VERSION ""

NS_ :

BS_:

BU_: TCU CANedge BMS TempSense INV U2C VCU

BO_ 3221225472 VECTOR__INDEPENDENT_SIG_MSG: 0 Vector__XXX
 SG_ ShockTravel_RL : 0|8@1+ (1,0) [0|255] "" Vector__XXX
 SG_ ShockTravel_RR : 0|8@1+ (1,0) [0|255] "" Vector__XXX
 SG_ ShockTravel_FL : 0|8@1+ (1,0) [0|255] "" Vector__XXX
 SG_ ShockTravel_FR : 0|8@1+ (1,0) [0|255] "" Vector__XXX

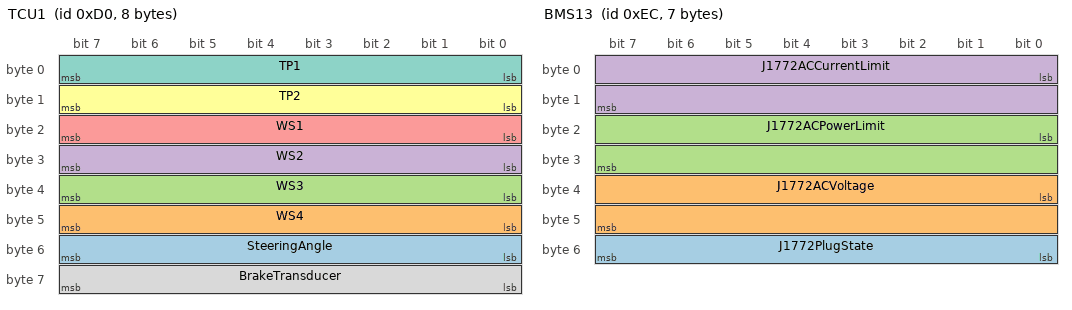
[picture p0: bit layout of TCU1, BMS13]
BO_ 208 TCU1: 8 TCU
 SG_ SteeringAngle : 48|8@1- (1,0) [-128|127] ""  CANedge
 SG_ WS4 : 40|8@1+ (1,0) [0|255] ""  CANedge
 SG_ WS3 : 32|8@1+ (1,0) [0|255] ""  CANedge
 SG_ WS2 : 24|8@1+ (1,0) [0|255] ""  CANedge
 SG_ WS1 : 16|8@1+ (1,0) [0|255] ""  CANedge
 SG_ TP2 : 8|8@1+ (1,0) [0|100] "%"  CANedge
 SG_ TP1 : 0|8@1+ (1,0) [0|100] "%"  CANedge
 SG_ BrakeTransducer : 56|8@1+ (1,0) [0|0] ""  CANedge

BO_ 237 BMS14: 4 BMS
 SG_ DTCStatus2 : 16|16@1+ (1,0) [0|65535] ""  CANedge
 SG_ DTCStatus1 : 0|16@1+ (1,0) [0|65535] ""  CANedge

BO_ 236 BMS13: 7 BMS
 SG_ J1772PlugState : 48|8@1+ (1,0) [0|4] ""  CANedge
 SG_ J1772ACVoltage : 32|16@1+ (0.1,0) [0|0] "VAC"  CANedge
 SG_ J1772ACPowerLimit : 16|16@1+ (1,0) [0|0] "WattAC"  CANedge
 SG_ J1772ACCurrentLimit : 0|16@1+ (1,0) [0|0] "AmpAC"  CANedge

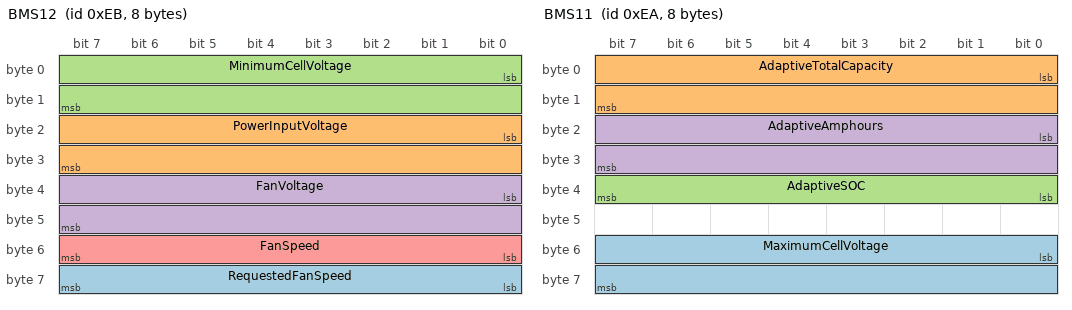
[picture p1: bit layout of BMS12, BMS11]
BO_ 235 BMS12: 8 BMS
 SG_ RequestedFanSpeed : 56|8@1+ (1,0) [0|6] ""  CANedge
 SG_ PowerInputVoltage : 16|16@1+ (0.1,0) [0|0] "V"  CANedge
 SG_ MinimumCellVoltage : 0|16@1+ (0.0001,0) [0|6.5535] "V"  CANedge
 SG_ FanVoltage : 32|16@1+ (0.01,0) [0|0] "V"  CANedge
 SG_ FanSpeed : 48|8@1+ (1,0) [0|6] ""  CANedge

BO_ 234 BMS11: 8 BMS
 SG_ MaximumCellVoltage : 48|16@1+ (0.0001,0) [0|6.5535] "V"  CANedge
 SG_ AdaptiveTotalCapacity : 0|16@1+ (0.1,0) [0|0] "Ah"  CANedge
 SG_ AdaptiveSOC : 32|8@1+ (0.5,0) [0|100] "%"  CANedge
 SG_ AdaptiveAmphours : 16|16@1+ (0.1,0) [0|0] "Ah"  CANedge

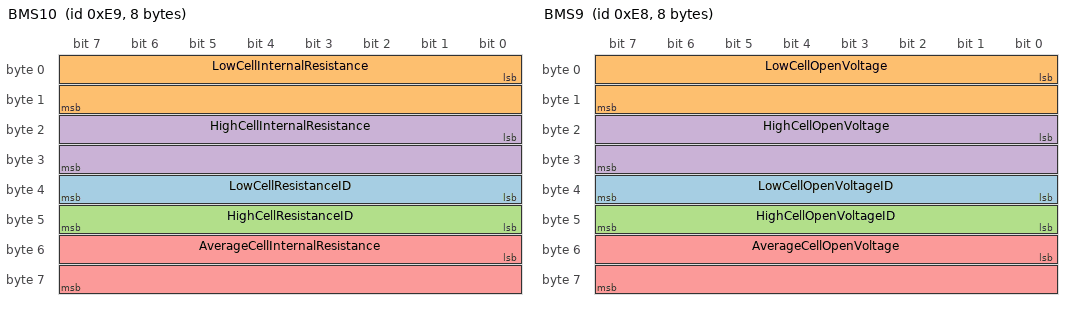
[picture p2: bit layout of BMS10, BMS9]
BO_ 233 BMS10: 8 BMS
 SG_ LowCellResistanceID : 32|8@1+ (1,0) [1|180] ""  CANedge
 SG_ LowCellInternalResistance : 0|16@1+ (0.01,0) [0|0] "mOhm"  CANedge
 SG_ HighCellResistanceID : 40|8@1+ (1,0) [1|180] ""  CANedge
 SG_ HighCellInternalResistance : 16|16@1+ (0.01,0) [0|0] "mOhm"  CANedge
 SG_ AverageCellInternalResistance : 48|16@1+ (0.01,0) [0|0] "mOhm"  CANedge

BO_ 232 BMS9: 8 BMS
 SG_ LowCellOpenVoltageID : 32|8@1+ (1,0) [1|180] ""  CANedge
 SG_ LowCellOpenVoltage : 0|16@1+ (0.0001,0) [0|6.5535] "V"  CANedge
 SG_ HighCellOpenVoltageID : 40|8@1+ (1,0) [1|180] ""  CANedge
 SG_ HighCellOpenVoltage : 16|16@1+ (0.0001,0) [0|6.5535] "V"  CANedge
 SG_ AverageCellOpenVoltage : 48|16@1+ (0.0001,0) [0|6.5535] "V"  CANedge

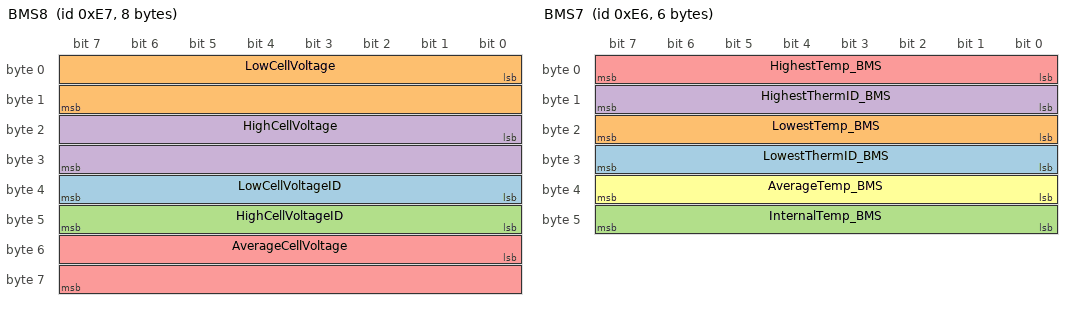
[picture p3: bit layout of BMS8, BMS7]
BO_ 231 BMS8: 8 BMS
 SG_ LowCellVoltageID : 32|8@1+ (1,0) [1|180] ""  CANedge
 SG_ LowCellVoltage : 0|16@1+ (0.0001,0) [0|6.5535] "V"  CANedge
 SG_ HighCellVoltageID : 40|8@1+ (1,0) [1|180] ""  CANedge
 SG_ HighCellVoltage : 16|16@1+ (0.0001,0) [0|6.5535] "V"  CANedge
 SG_ AverageCellVoltage : 48|16@1+ (0.0001,0) [0|6.5535] "V"  CANedge

BO_ 230 BMS7: 6 BMS
 SG_ LowestThermID_BMS : 24|8@1+ (1,0) [1|80] ""  CANedge
 SG_ LowestTemp_BMS : 16|8@1- (1,0) [0|255] "C"  CANedge
 SG_ InternalTemp_BMS : 40|8@1- (1,0) [0|255] "C"  CANedge
 SG_ HighestThermID_BMS : 8|8@1+ (1,0) [1|80] ""  CANedge
 SG_ HighestTemp_BMS : 0|8@1- (1,0) [0|255] "C"  CANedge
 SG_ AverageTemp_BMS : 32|8@1- (1,0) [0|255] "C"  CANedge

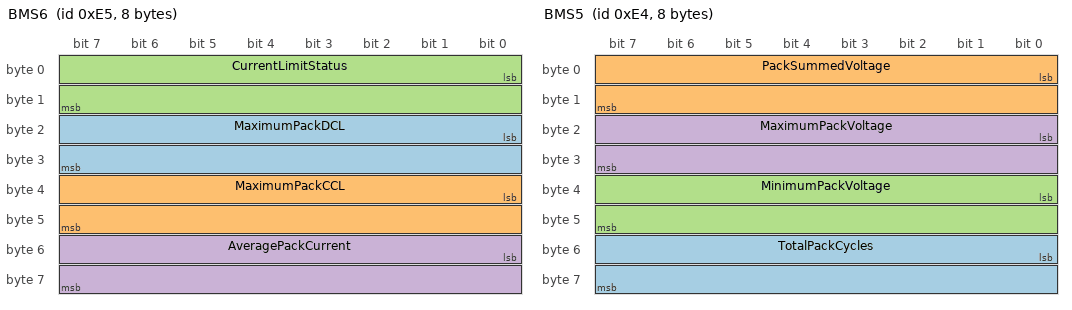
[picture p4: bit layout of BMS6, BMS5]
BO_ 229 BMS6: 8 BMS
 SG_ MaximumPackDCL : 16|16@1+ (1,0) [0|0] "A"  CANedge
 SG_ MaximumPackCCL : 32|16@1+ (1,0) [0|0] "A"  CANedge
 SG_ CurrentLimitStatus : 0|16@1+ (1,0) [0|65535] ""  CANedge
 SG_ AveragePackCurrent : 48|16@1+ (0.1,0) [0|0] "A"  CANedge

BO_ 228 BMS5: 8 BMS
 SG_ TotalPackCycles : 48|16@1+ (1,0) [0|0] "cycle"  CANedge
 SG_ PackSummedVoltage : 0|16@1+ (0.1,0) [0|0] "V"  CANedge
 SG_ MinimumPackVoltage : 32|16@1+ (0.1,0) [0|0] "V"  CANedge
 SG_ MaximumPackVoltage : 16|16@1+ (0.1,0) [0|0] "V"  CANedge

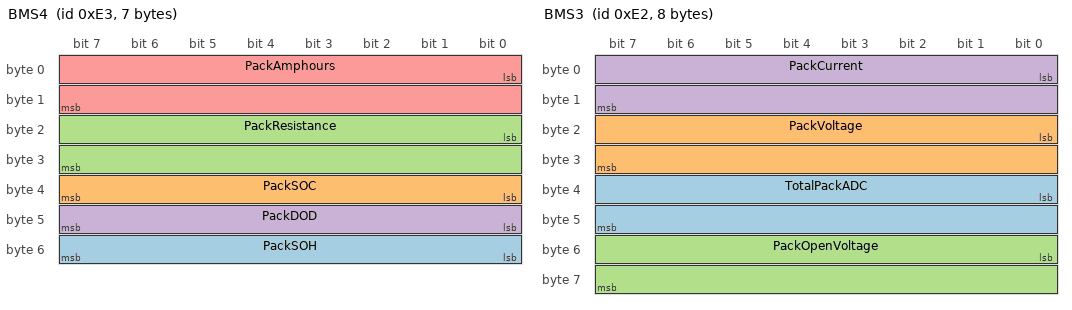
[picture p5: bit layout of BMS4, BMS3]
BO_ 227 BMS4: 7 BMS
 SG_ PackSOH : 48|8@1+ (1,0) [0|100] "%"  CANedge
 SG_ PackSOC : 32|8@1+ (0.5,0) [0|100] "%"  CANedge
 SG_ PackResistance : 16|16@1+ (1,0) [0|0] "mOhm"  CANedge
 SG_ PackDOD : 40|8@1+ (0.5,0) [0|100] "%"  CANedge
 SG_ PackAmphours : 0|16@1+ (0.1,0) [0|0] "Ahr"  CANedge

BO_ 226 BMS3: 8 BMS
 SG_ TotalPackADC : 32|16@1+ (0.1,0) [0|0] "V"  CANedge
 SG_ PackVoltage : 16|16@1+ (0.1,0) [0|0] "V"  CANedge
 SG_ PackOpenVoltage : 48|16@1+ (0.1,0) [0|0] "V"  CANedge
 SG_ PackCurrent : 0|16@1+ (0.1,0) [0|0] "A"  CANedge

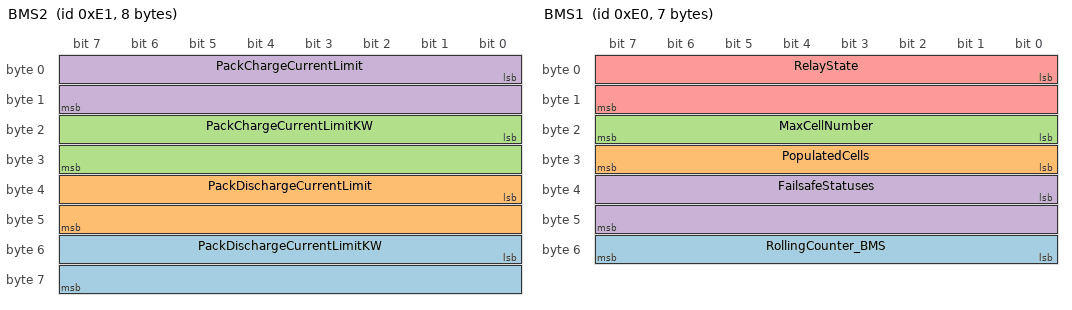
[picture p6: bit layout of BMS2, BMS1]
BO_ 225 BMS2: 8 BMS
 SG_ PackDischargeCurrentLimitKW : 48|16@1+ (0.1,0) [0|0] "kW"  CANedge
 SG_ PackDischargeCurrentLimit : 32|16@1+ (1,0) [0|0] "A"  CANedge
 SG_ PackChargeCurrentLimitKW : 16|16@1+ (0.1,0) [0|0] "kW"  CANedge
 SG_ PackChargeCurrentLimit : 0|16@1+ (1,0) [0|0] "A"  CANedge

BO_ 224 BMS1: 7 BMS
 SG_ RollingCounter_BMS : 48|8@1+ (1,0) [0|255] ""  CANedge
 SG_ PopulatedCells : 24|8@1+ (1,0) [0|255] ""  CANedge
 SG_ MaxCellNumber : 16|8@1+ (1,0) [0|255] ""  CANedge
 SG_ FailsafeStatuses : 32|16@1+ (1,0) [0|65535] ""  CANedge
 SG_ RelayState : 0|16@1+ (1,0) [0|65535] ""  CANedge

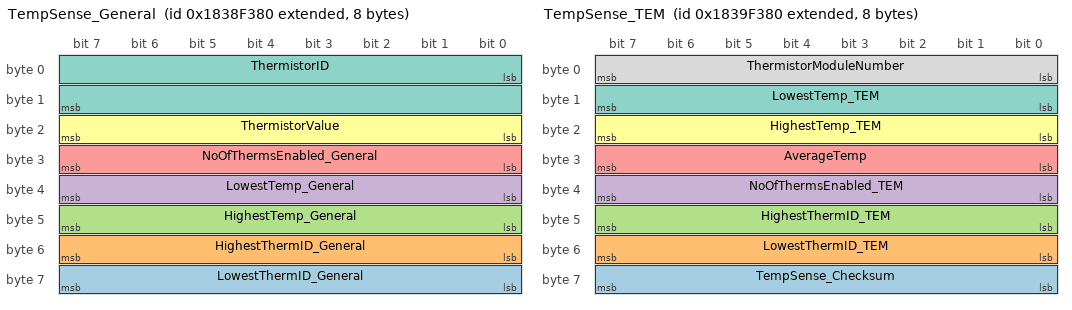
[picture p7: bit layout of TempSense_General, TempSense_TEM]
BO_ 2553869184 TempSense_General: 8 TempSense
 SG_ LowestThermID_General : 56|8@1+ (1,0) [0|79] ""  CANedge
 SG_ HighestThermID_General : 48|8@1+ (1,0) [0|79] ""  CANedge
 SG_ HighestTemp_General : 40|8@1- (1,0) [0|255] "C"  CANedge
 SG_ LowestTemp_General : 32|8@1- (1,0) [0|255] "C"  CANedge
 SG_ NoOfThermsEnabled_General : 24|8@1+ (1,0) [0|80] ""  CANedge
 SG_ ThermistorValue : 16|8@1- (1,0) [0|255] "C"  CANedge
 SG_ ThermistorID : 0|16@1+ (1,0) [0|799] ""  CANedge

BO_ 2553934720 TempSense_TEM: 8 TempSense
 SG_ TempSense_Checksum : 56|8@1+ (1,0) [0|255] ""  CANedge,BMS
 SG_ LowestThermID_TEM : 48|8@1+ (1,0) [0|79] ""  CANedge,BMS
 SG_ HighestThermID_TEM : 40|8@1+ (1,0) [0|79] ""  CANedge,BMS
 SG_ NoOfThermsEnabled_TEM : 32|8@1+ (1,0) [0|80] ""  CANedge,BMS
 SG_ AverageTemp : 24|8@1- (1,0) [0|255] "C"  CANedge,BMS
 SG_ HighestTemp_TEM : 16|8@1- (1,0) [0|255] "C"  CANedge,BMS
 SG_ LowestTemp_TEM : 8|8@1- (1,0) [0|255] "C"  CANedge,BMS
 SG_ ThermistorModuleNumber : 0|8@1+ (1,0) [0|9] ""  CANedge,BMS

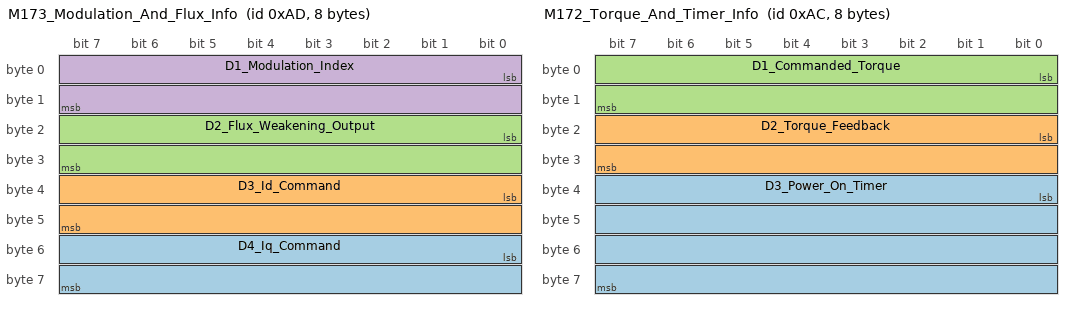
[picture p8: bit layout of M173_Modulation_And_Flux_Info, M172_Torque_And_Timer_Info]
BO_ 173 M173_Modulation_And_Flux_Info: 8 INV
 SG_ D4_Iq_Command : 48|16@1- (0.1,0) [-3276.8|3276.7] "A"  CANedge
 SG_ D3_Id_Command : 32|16@1- (0.1,0) [-3276.8|3276.7] "A"  CANedge
 SG_ D2_Flux_Weakening_Output : 16|16@1- (0.1,0) [-3276.8|3276.7] "A"  CANedge
 SG_ D1_Modulation_Index : 0|16@1- (0.0001,0) [-3.2768|3.2767] ""  CANedge

BO_ 172 M172_Torque_And_Timer_Info: 8 INV
 SG_ D3_Power_On_Timer : 32|32@1+ (0.003,0) [0|12884800] "Sec"  CANedge
 SG_ D2_Torque_Feedback : 16|16@1- (0.1,0) [-3276.8|3276.7] "Nm"  CANedge
 SG_ D1_Commanded_Torque : 0|16@1- (0.1,0) [-3276.8|3276.7] "Nm"  CANedge

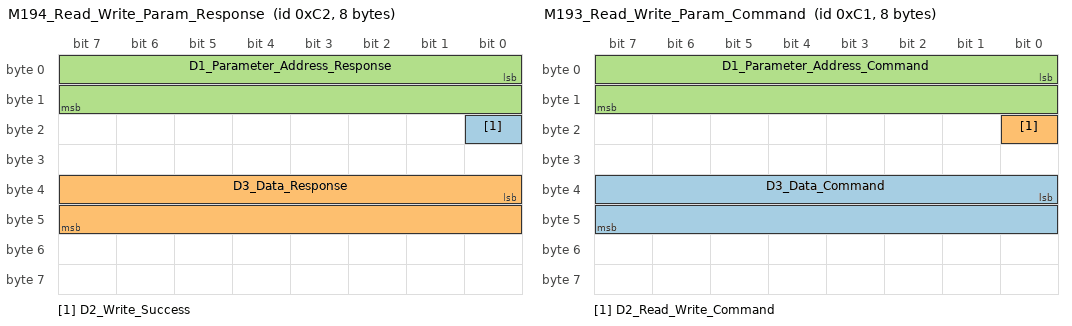
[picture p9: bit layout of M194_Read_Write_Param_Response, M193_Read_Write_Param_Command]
BO_ 194 M194_Read_Write_Param_Response: 8 INV
 SG_ D2_Write_Success : 16|1@1+ (1,0) [0|1] ""  CANedge
 SG_ D3_Data_Response : 32|16@1- (1,0) [-32768|32767] ""  CANedge
 SG_ D1_Parameter_Address_Response : 0|16@1+ (1,0) [0|65535] ""  CANedge

BO_ 193 M193_Read_Write_Param_Command: 8 VCU
 SG_ D3_Data_Command : 32|16@1- (1,0) [-32768|32767] ""  CANedge
 SG_ D2_Read_Write_Command : 16|1@1+ (1,0) [0|1] ""  CANedge
 SG_ D1_Parameter_Address_Command : 0|16@1+ (1,0) [0|65535] ""  CANedge

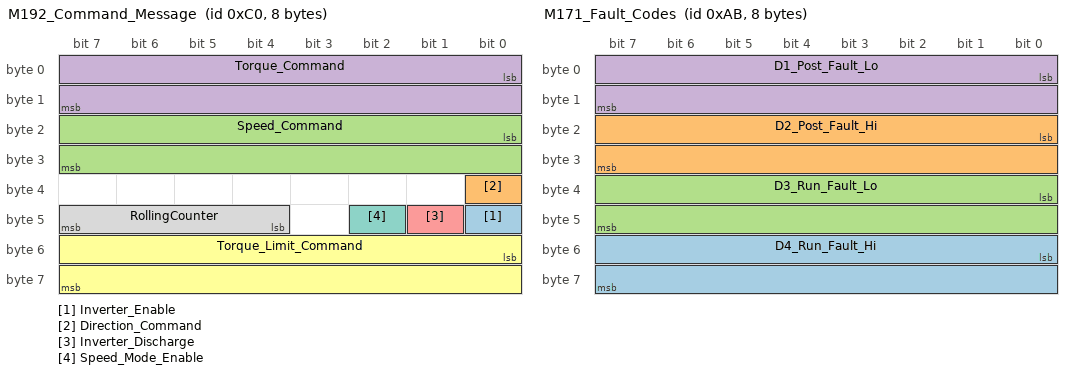
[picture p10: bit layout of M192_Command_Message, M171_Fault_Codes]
BO_ 192 M192_Command_Message: 8 VCU
 SG_ Inverter_Enable : 40|1@1+ (1,0) [0|1] "Bit"  CANedge
 SG_ Direction_Command : 32|1@1+ (1,0) [0|1] "Bit"  CANedge
 SG_ Speed_Command : 16|16@1- (1,0) [-32768|32767] "rpm"  CANedge
 SG_ Torque_Command : 0|16@1- (0.1,0) [-3276.8|3276.7] "Nm"  CANedge
 SG_ Inverter_Discharge : 41|1@1+ (1,0) [0|1] "Bit"  CANedge
 SG_ Torque_Limit_Command : 48|16@1- (0.1,0) [-3276.8|3276.7] "Nm"  CANedge
 SG_ Speed_Mode_Enable : 42|1@1+ (1,0) [0|1] "Bit"  CANedge
 SG_ RollingCounter : 44|4@1+ (1,0) [0|15] "Bits"  CANedge

BO_ 171 M171_Fault_Codes: 8 INV
 SG_ D4_Run_Fault_Hi : 48|16@1+ (1,0) [0|65535] ""  CANedge
 SG_ D2_Post_Fault_Hi : 16|16@1+ (1,0) [0|65535] ""  CANedge
 SG_ D3_Run_Fault_Lo : 32|16@1+ (1,0) [0|65535] ""  CANedge
 SG_ D1_Post_Fault_Lo : 0|16@1+ (1,0) [0|65535] ""  CANedge

BO_ 170 M170_Internal_States: 8 INV
 SG_ D7_Direction_Command : 56|1@1+ (1,0) [0|1] ""  CANedge
 SG_ D6_Inverter_Enable_State : 48|1@1+ (1,0) [0|1] ""  CANedge
 SG_ D3_Relay_3_Status : 26|1@1+ (1,0) [0|1] ""  CANedge
 SG_ D3_Relay_4_Status : 27|1@1+ (1,0) [0|1] ""  CANedge
 SG_ D3_Relay_2_Status : 25|1@1+ (1,0) [0|1] ""  CANedge
 SG_ D4_Inverter_Run_Mode : 32|1@1+ (1,0) [0|1] ""  CANedge
 SG_ D5_Inverter_Command_Mode : 40|1@1+ (1,0) [0|1] ""  CANedge
 SG_ D3_Relay_1_Status : 24|1@1+ (1,0) [0|1] ""  CANedge
 SG_ D2_Inverter_State : 16|8@1+ (1,0) [0|255] ""  CANedge
 SG_ D1_VSM_State : 0|8@1+ (1,0) [0|15] ""  CANedge
 SG_ D6_Inverter_Enable_Lockout : 55|1@1+ (1,0) [0|1] ""  CANedge
 SG_ D4_Inverter_Discharge_State : 37|3@1+ (1,0) [0|7] ""  CANedge
 SG_ D3_Relay_5_Status : 28|1@1+ (1,0) [0|1] ""  CANedge
 SG_ D3_Relay_6_Status : 29|1@1+ (1,0) [0|1] ""  CANedge
 SG_ D7_BMS_Active : 57|1@1+ (1,0) [0|1] ""  CANedge
 SG_ D7_BMS_Torque_Limiting : 58|1@1+ (1,0) [0|1] ""  CANedge
 SG_ D7_Max_Speed_Limiting : 59|1@1+ (1,0) [0|1] ""  CANedge
 SG_ D7_Low_Speed_Limiting : 61|1@1+ (1,0) [0|1] ""  CANedge
 SG_ D5_Rolling_Counter : 44|4@1+ (1,0) [0|15] ""  CANedge
 SG_ D1_PWM_Frequency : 8|8@1+ (1,0) [0|255] "kHz"  CANedge
 SG_ D6_Start_Mode_Active : 54|1@1+ (1,0) [0|1] ""  CANedge

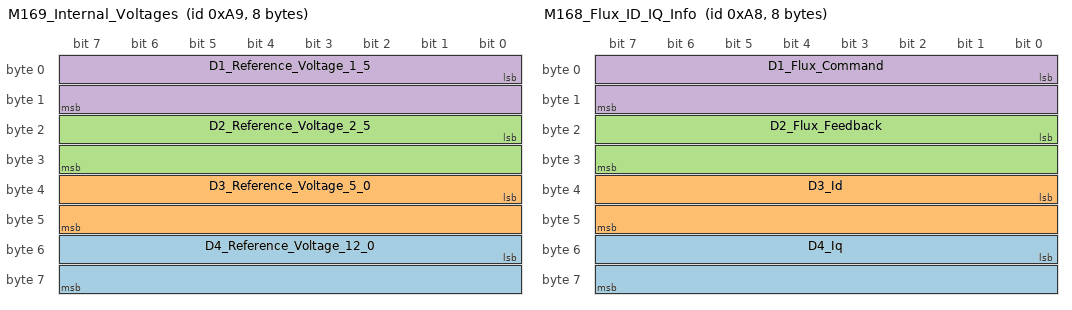
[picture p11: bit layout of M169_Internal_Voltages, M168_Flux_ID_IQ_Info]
BO_ 169 M169_Internal_Voltages: 8 INV
 SG_ D4_Reference_Voltage_12_0 : 48|16@1- (0.01,0) [-327.68|327.67] "V"  CANedge
 SG_ D3_Reference_Voltage_5_0 : 32|16@1- (0.01,0) [-327.68|327.67] "V"  CANedge
 SG_ D2_Reference_Voltage_2_5 : 16|16@1- (0.01,0) [-327.68|327.67] "V"  CANedge
 SG_ D1_Reference_Voltage_1_5 : 0|16@1- (0.01,0) [-327.68|327.67] "V"  CANedge

BO_ 168 M168_Flux_ID_IQ_Info: 8 INV
 SG_ D4_Iq : 48|16@1- (0.1,0) [-3276.8|3276.7] "A"  CANedge
 SG_ D3_Id : 32|16@1- (0.1,0) [-3276.8|3276.7] "A"  CANedge
 SG_ D2_Flux_Feedback : 16|16@1- (0.001,0) [-32.768|32.767] "Wb"  CANedge
 SG_ D1_Flux_Command : 0|16@1- (0.001,0) [-32.768|32.767] "Wb"  CANedge

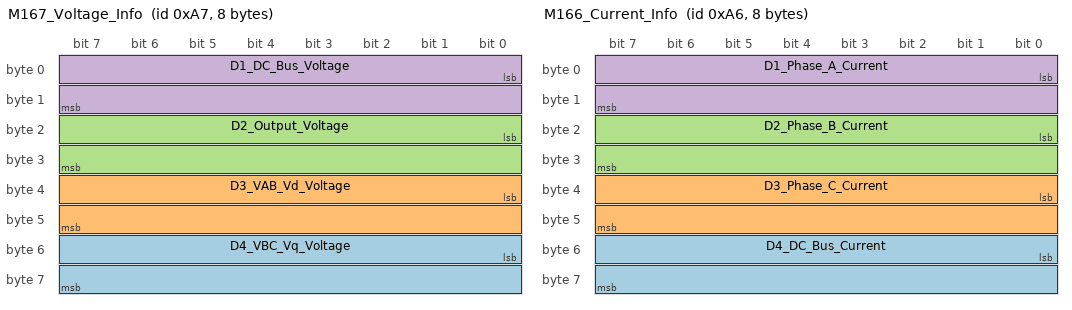
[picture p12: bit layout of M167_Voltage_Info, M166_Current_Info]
BO_ 167 M167_Voltage_Info: 8 INV
 SG_ D4_VBC_Vq_Voltage : 48|16@1- (0.1,0) [-3276.8|3276.7] "V"  CANedge
 SG_ D3_VAB_Vd_Voltage : 32|16@1- (0.1,0) [-3276.8|3276.7] "V"  CANedge
 SG_ D2_Output_Voltage : 16|16@1- (0.1,0) [-3276.8|3276.7] "V"  CANedge
 SG_ D1_DC_Bus_Voltage : 0|16@1- (0.1,0) [-3276.8|3276.7] "V"  CANedge

BO_ 166 M166_Current_Info: 8 INV
 SG_ D4_DC_Bus_Current : 48|16@1- (0.1,0) [-3276.8|3276.7] "A"  CANedge
 SG_ D3_Phase_C_Current : 32|16@1- (0.1,0) [-3276.8|3276.7] "A"  CANedge
 SG_ D2_Phase_B_Current : 16|16@1- (0.1,0) [-3276.8|3276.7] "A"  CANedge
 SG_ D1_Phase_A_Current : 0|16@1- (0.1,0) [-3276.8|3276.7] "A"  CANedge

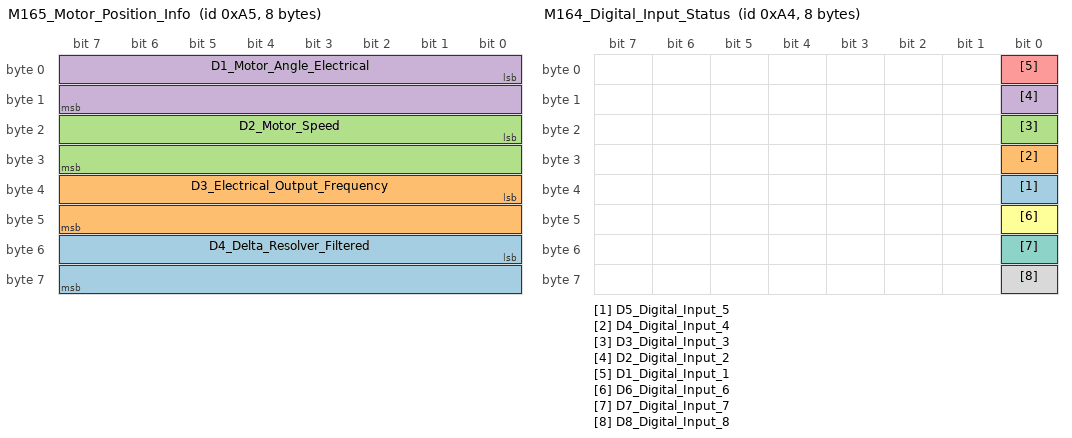
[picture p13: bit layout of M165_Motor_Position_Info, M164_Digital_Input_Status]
BO_ 165 M165_Motor_Position_Info: 8 INV
 SG_ D4_Delta_Resolver_Filtered : 48|16@1- (0.1,0) [-3276.8|3276.7] "deg"  CANedge
 SG_ D3_Electrical_Output_Frequency : 32|16@1- (0.1,0) [-3276.8|3276.7] "hz"  CANedge
 SG_ D2_Motor_Speed : 16|16@1- (1,0) [-32768|32767] "rpm"  CANedge
 SG_ D1_Motor_Angle_Electrical : 0|16@1+ (0.1,0) [0|6553.5] "deg"  CANedge

BO_ 164 M164_Digital_Input_Status: 8 INV
 SG_ D5_Digital_Input_5 : 32|1@1+ (1,0) [0|1] "boolean"  CANedge
 SG_ D4_Digital_Input_4 : 24|1@1+ (1,0) [0|1] "boolean"  CANedge
 SG_ D3_Digital_Input_3 : 16|1@1+ (1,0) [0|1] "boolean"  CANedge
 SG_ D2_Digital_Input_2 : 8|1@1+ (1,0) [0|1] "boolean"  CANedge
 SG_ D1_Digital_Input_1 : 0|1@1+ (1,0) [0|1] "boolean"  CANedge
 SG_ D6_Digital_Input_6 : 40|1@1+ (1,0) [0|1] "boolean"  CANedge
 SG_ D7_Digital_Input_7 : 48|1@1+ (1,0) [0|1] "boolean"  CANedge
 SG_ D8_Digital_Input_8 : 56|1@1+ (1,0) [0|1] "boolean"  CANedge

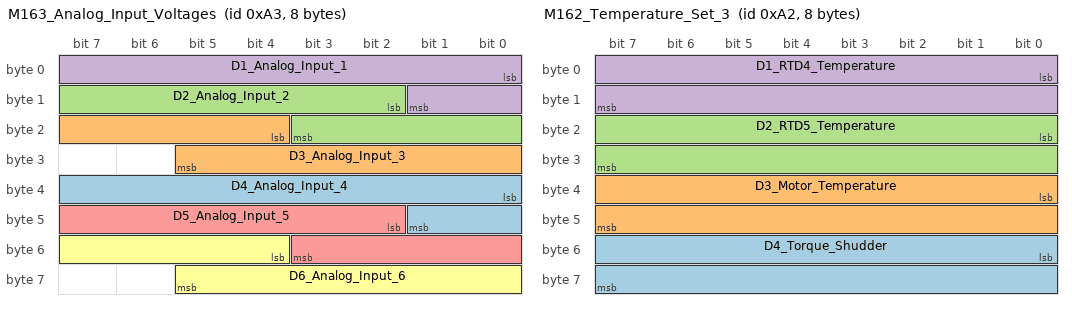
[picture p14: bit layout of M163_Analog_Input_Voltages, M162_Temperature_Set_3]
BO_ 163 M163_Analog_Input_Voltages: 8 INV
 SG_ D4_Analog_Input_4 : 32|10@1+ (0.01,0) [0|10.23] "V"  CANedge
 SG_ D3_Analog_Input_3 : 20|10@1+ (0.01,0) [0|10.23] "V"  CANedge
 SG_ D2_Analog_Input_2 : 10|10@1+ (0.01,0) [0|10.23] "V"  CANedge
 SG_ D1_Analog_Input_1 : 0|10@1+ (0.01,0) [0|10.23] "V"  CANedge
 SG_ D5_Analog_Input_5 : 42|10@1+ (0.01,0) [0|10.23] "V"  CANedge
 SG_ D6_Analog_Input_6 : 52|10@1+ (0.01,0) [0|10.23] "V"  CANedge

BO_ 162 M162_Temperature_Set_3: 8 INV
 SG_ D4_Torque_Shudder : 48|16@1- (0.1,0) [-3276.8|3276.7] "Nm"  CANedge
 SG_ D3_Motor_Temperature : 32|16@1- (0.1,0) [-3276.8|3276.7] "degC"  CANedge
 SG_ D2_RTD5_Temperature : 16|16@1- (0.1,0) [-3276.8|3276.7] "degC"  CANedge
 SG_ D1_RTD4_Temperature : 0|16@1- (0.1,0) [-3276.8|3276.7] "degC"  CANedge

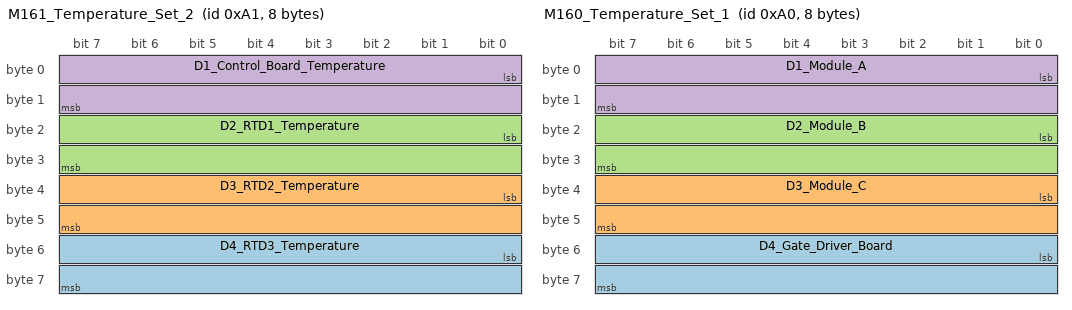
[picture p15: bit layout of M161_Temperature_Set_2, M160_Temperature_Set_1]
BO_ 161 M161_Temperature_Set_2: 8 INV
 SG_ D4_RTD3_Temperature : 48|16@1- (0.1,0) [-3276.8|3276.7] "degC"  CANedge
 SG_ D3_RTD2_Temperature : 32|16@1- (0.1,0) [-3276.8|3276.7] "degC"  CANedge
 SG_ D2_RTD1_Temperature : 16|16@1- (0.1,0) [-3276.8|3276.7] "degC"  CANedge
 SG_ D1_Control_Board_Temperature : 0|16@1- (0.1,0) [-3276.8|3276.7] "degC"  CANedge

BO_ 160 M160_Temperature_Set_1: 8 INV
 SG_ D4_Gate_Driver_Board : 48|16@1- (0.1,0) [-3276.8|3276.7] "degC"  CANedge
 SG_ D3_Module_C : 32|16@1- (0.1,0) [-3276.8|3276.7] "degC"  CANedge
 SG_ D2_Module_B : 16|16@1- (0.1,0) [-3276.8|3276.7] "degC"  CANedge
 SG_ D1_Module_A : 0|16@1- (0.1,0) [-3276.8|3276.7] "degC"  CANedge

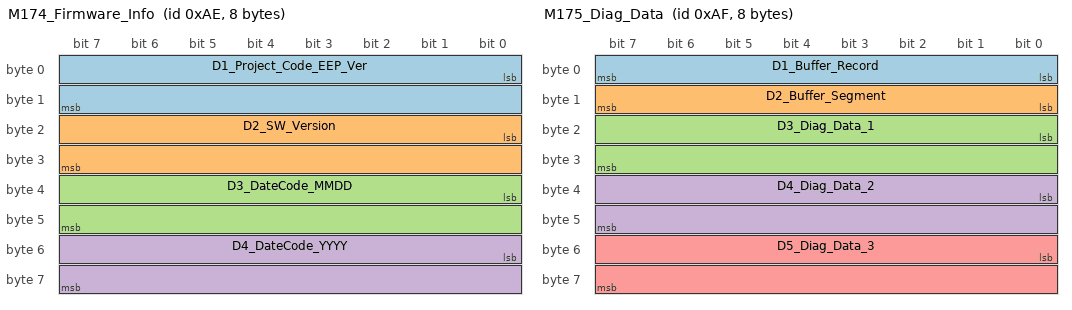
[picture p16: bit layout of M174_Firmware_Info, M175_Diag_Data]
BO_ 174 M174_Firmware_Info: 8 INV
 SG_ D1_Project_Code_EEP_Ver : 0|16@1+ (1,0) [0|65535] ""  CANedge
 SG_ D2_SW_Version : 16|16@1+ (1,0) [0|65535] ""  CANedge
 SG_ D3_DateCode_MMDD : 32|16@1+ (1,0) [0|65535] ""  CANedge
 SG_ D4_DateCode_YYYY : 48|16@1+ (1,0) [0|65535] ""  CANedge

BO_ 175 M175_Diag_Data: 8 INV
 SG_ D1_Buffer_Record : 0|8@1+ (1,0) [0|255] ""  CANedge
 SG_ D2_Buffer_Segment : 8|8@1+ (1,0) [0|5] ""  CANedge
 SG_ D3_Diag_Data_1 : 16|16@1- (1,0) [-32768|32767] ""  CANedge
 SG_ D4_Diag_Data_2 : 32|16@1- (1,0) [-32768|32767] ""  CANedge
 SG_ D5_Diag_Data_3 : 48|16@1- (1,0) [-32768|32767] ""  CANedge

BO_ 471 M187_U2C_Command_Txd: 8 INV
 SG_ D1_ID_Byte : 0|8@1+ (1,0) [0|255] ""  CANedge
 SG_ D2_Setpoint_Calc : 8|8@1+ (1,0) [0|255] ""  CANedge

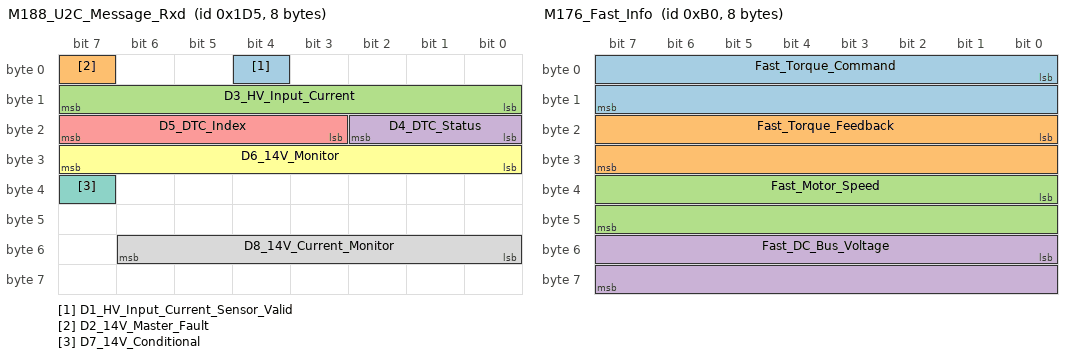
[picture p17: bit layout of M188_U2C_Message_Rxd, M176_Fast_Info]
BO_ 469 M188_U2C_Message_Rxd: 8 U2C
 SG_ D1_HV_Input_Current_Sensor_Valid : 4|1@1+ (1,0) [0|1] ""  CANedge
 SG_ D2_14V_Master_Fault : 7|1@1+ (1,0) [0|1] ""  CANedge
 SG_ D3_HV_Input_Current : 8|8@1+ (1,0) [0|255] ""  CANedge
 SG_ D4_DTC_Status : 16|3@1+ (1,0) [0|7] ""  CANedge
 SG_ D5_DTC_Index : 19|5@1+ (1,0) [0|31] ""  CANedge
 SG_ D6_14V_Monitor : 24|8@1+ (1,0) [0|255] ""  CANedge
 SG_ D7_14V_Conditional : 39|1@1+ (1,0) [0|1] ""  CANedge
 SG_ D8_14V_Current_Monitor : 48|7@1+ (1,0) [0|127] ""  CANedge

BO_ 514 BMS_Current_Limit: 8 BMS
 SG_ D1_Max_Discharge_Current : 0|16@1+ (1,0) [0|1000] "A"  CANedge
 SG_ D2_Max_Charge_Current : 16|16@1+ (1,0) [0|1000] "A"  CANedge

BO_ 176 M176_Fast_Info: 8 INV
 SG_ Fast_Torque_Command : 0|16@1- (0.1,0) [-3276.8|3276.7] "Nm"  CANedge
 SG_ Fast_Torque_Feedback : 16|16@1- (0.1,0) [-3276.8|3276.7] "Nm"  CANedge
 SG_ Fast_Motor_Speed : 32|16@1- (1,0) [-32768|32767] "rpm"  CANedge
 SG_ Fast_DC_Bus_Voltage : 48|16@1- (0.1,0) [-3276.8|3276.7] "V"  CANedge

CM_ BU_ BMS "BMS Master";
CM_ BU_ INV "The Cascadia Motion inverter";
CM_ BU_ U2C "Delphi DC/DC Converter";
CM_ BU_ VCU "The system vehicle control unit";
CM_ BO_ 3221225472 "This is a message for not used signals, created by Vector CANdb++ DBC OLE DB Provider.";
CM_ SG_ 229 CurrentLimitStatus "This value is provided so the reasons for why a current limit (either Charge Current Limit or Discharge Current Limit are being reduced by the BMS from the maximum allowable current.";
CM_ SG_ 229 AveragePackCurrent "This is the AVERAGE current pack amperage value for the battery pack. This will report a constant 0 if no current sensor is selected. The average is taken over the last 1 second of operation so it will lag the instantaneous pack current value.";
CM_ SG_ 228 TotalPackCycles "This is the total number of cycles that the battery pack has been put through since the BMS has started keeping track.";
CM_ SG_ 228 PackSummedVoltage "This value is the sum of all the cells being monitored by the BMS. This is different from the Pack Voltage value because that is derived from the redundant total pack voltage sensor rather than summing up all of the cells.";
CM_ SG_ 228 MinimumPackVoltage "This value is the minimum pack voltage that the BMS is using to limit how low the pack voltage is allowed to be pulled down to.";
CM_ SG_ 228 MaximumPackVoltage "This value is the maximum pack voltage that the BMS is using to limit how high the pack voltage can be.";
CM_ SG_ 227 PackDOD "This value reperesents the total pack depth of discharge (that is, the total percent of the battery that has been discharged to this point). This value does not account for any Drift.";
CM_ SG_ 227 PackAmphours "This is the calculated number of amphours remaining in the battery pack. This is used in part to calculate State of Charge.";
CM_ SG_ 226 TotalPackADC "This is the raw voltage value from the total pack voltage sensor (NOT the sum of all the cell voltages). Only available on BMS models that support the separate total pack sensor.";
CM_ SG_ 226 PackCurrent "This is the current pack amperage value for the battery pack. This will report a constant 0 if no current sensor is selected.";
CM_ SG_ 225 PackDischargeCurrentLimitKW "This is the pack Charge Current Limit expressed in kilowatts.";
CM_ SG_ 225 PackChargeCurrentLimitKW "This is the pack Charge Current Limit expressed in kilowatts.";
CM_ SG_ 225 PackChargeCurrentLimit "The value is, by default, reported as a positive value from 0 to whatever the maximum charge current limit is set to.";
CM_ SG_ 224 RollingCounter_BMS "This is a sanity-check value that increments automatically by 1 once every 100ms (maximum value is 255, after which it resets to 0 and starts again).";
CM_ SG_ 224 PopulatedCells "This represents the total number of populated (active) cells in the BMS. This is can be equal to or lower than the Max Cell Number.";
CM_ SG_ 224 MaxCellNumber "This value represents the maximum number of cells that the BMS is capable of supporting. This value is determined by what hardware version of the BMS was purchased.";
CM_ SG_ 224 FailsafeStatuses "This parameter contains the status of all the BMS failsafe modes";
CM_ SG_ 224 RelayState "This parameter contains the status (active state) of all the BMS outputs and inputs.";
CM_ BO_ 2553869184 "Thermistor General Broadcast";
CM_ SG_ 2553869184 LowestThermID_General "Orion BMS2: Max number of thermistors supported per expansion module = 80";
CM_ SG_ 2553869184 HighestThermID_General "Orion BMS2: Max number of thermistors supported per expansion module = 80";
CM_ SG_ 2553869184 NoOfThermsEnabled_General "Orion BMS2: Max number of thermistors supported per expansion module = 80";
CM_ SG_ 2553869184 ThermistorID "Orion BMS2:
Max number of thermistor expansion modules supported: 10
Max number of thermistors supported per module: 80
Max thermistors = 800";
CM_ BO_ 2553934720 "Thermistor Module -> BMS Broadcast";
CM_ SG_ 2553934720 LowestThermID_TEM "Orion BMS2: Max number of thermistors supported per expansion module = 80";
CM_ SG_ 2553934720 HighestThermID_TEM "Orion BMS2: Max number of thermistors supported per expansion module = 80";
CM_ SG_ 2553934720 NoOfThermsEnabled_TEM "Orion BMS2: Max number of thermistors supported per expansion module = 80";
CM_ SG_ 2553934720 ThermistorModuleNumber "Orion BMS2: Max number of thermistor modules supported = 10";
CM_ SG_ 173 D4_Iq_Command "The commanded Q-axis current";
CM_ SG_ 173 D3_Id_Command "The commanded D-axis current";
CM_ SG_ 173 D2_Flux_Weakening_Output "This is the current output of the flux regulator.";
CM_ SG_ 173 D1_Modulation_Index "This is the modulation index. The scale factor is x100. To get the actual modulation index divide the value by 100.";
CM_ SG_ 172 D3_Power_On_Timer "Updated every 3 msec. This will roll over in approximately 150 days!";
CM_ SG_ 172 D2_Torque_Feedback "Estimated motor torque feedback";
CM_ SG_ 172 D1_Commanded_Torque "The commanded Torque";
CM_ BO_ 194 "The inverter response to each Parameter message that is received.";
CM_ SG_ 194 D2_Write_Success "0=Write failure, 1=Success";
CM_ SG_ 194 D3_Data_Response "All EEPROM data is 16 bits and is contained in bytes 4 and 5. Bytes 6 and 7 should be ignored.";
CM_ SG_ 194 D1_Parameter_Address_Response "Valid EEPROM Parameter CAN addresses are between 100 and 499.";
CM_ BO_ 193 "Parameter Message sent as needed by VCU to request info, change EEPROM, or command a function.";
CM_ SG_ 193 D3_Data_Command "All EEPROM data is 16 bits and is contained in bytes 4 and 5.";
CM_ SG_ 193 D2_Read_Write_Command "0=Read, 1=Write";
CM_ SG_ 193 D1_Parameter_Address_Command "Valid EEPROM Parameter CAN addresses are between 100 and 499.";
CM_ BO_ 192 "The command message is used to transmit data to the controller. This message is sent from a user supplied external controller to the PMxxx controller.";
CM_ SG_ 192 Inverter_Enable "0=Inverter OFF, 1 = Inverter ON";
CM_ SG_ 192 Direction_Command "0=CW, 1=CCW as veiwed from the shaft end of the motor";
CM_ SG_ 192 Speed_Command "Speed commandused when in speed mode";
CM_ SG_ 192 Torque_Command "Torque command when in torque mode";
CM_ SG_ 192 Inverter_Discharge "0=Discharge Disable,
=Discharge Enable";
CM_ SG_ 192 Torque_Limit_Command "Torque Limit, set to 0 to keep default";
CM_ SG_ 192 Speed_Mode_Enable "0 = No change to mode, 1 = change to speed mode from torque mode";
CM_ SG_ 192 RollingCounter "Rolling Counter command";
CM_ SG_ 171 D4_Run_Fault_Hi "Each bit represents a fault. Please refer to PM100 Users Manual for details.";
CM_ SG_ 171 D2_Post_Fault_Hi "Each bit represents a fault. Please refer to PM100 Users Manual for details.";
CM_ SG_ 171 D3_Run_Fault_Lo "Each bit represents a fault. Please refer to PM100 Users Manual for details.";
CM_ SG_ 171 D1_Post_Fault_Lo "Each bit represents a fault. Please refer to PM100 Users Manual for details.";
CM_ SG_ 170 D7_Direction_Command "1 = Forward
0 = 'Reverse' if inverter enabled  & 'Stopped' if inverter is disabled";
CM_ SG_ 170 D6_Inverter_Enable_State "0=Inverter Disabled, 
1=Inverter Enabled";
CM_ SG_ 170 D3_Relay_3_Status "0=OFF, 1=ON";
CM_ SG_ 170 D3_Relay_4_Status "0=OFF, 1=ON";
CM_ SG_ 170 D3_Relay_2_Status "0=OFF, 1=ON";
CM_ SG_ 170 D4_Inverter_Run_Mode "0=Torque Mode, 1=Speed Mode";
CM_ SG_ 170 D5_Inverter_Command_Mode "0=CAN mode, 1=VSM mode";
CM_ SG_ 170 D3_Relay_1_Status "0=OFF, 1=ON";
CM_ SG_ 170 D2_Inverter_State "Different states for the inverter state machine";
CM_ SG_ 170 D1_VSM_State "Different states for the vehicle state machine";
CM_ SG_ 170 D6_Inverter_Enable_Lockout "0=Lockout Disabled, 1=Lockout Enabled";
CM_ SG_ 170 D4_Inverter_Discharge_State "0 = Disabled, 1 = Enabled, 2 = Speed Check, 3 = Active, 4 = Complete";
CM_ SG_ 170 D3_Relay_5_Status "0=OFF, 1=ON";
CM_ SG_ 170 D3_Relay_6_Status "0=OFF, 1=ON";
CM_ SG_ 170 D7_BMS_Active "0 = BMS Not Active, 1 = BMS Active";
CM_ SG_ 170 D7_BMS_Torque_Limiting "0 = Not Limiting, 1 = Limiting";
CM_ SG_ 170 D7_Max_Speed_Limiting "0 = Not Limiting, 1 = torque limiting due to maximum speed";
CM_ SG_ 170 D7_Low_Speed_Limiting "0 = Not Limiting, 1 = Current limiting due to low motor speed";
CM_ SG_ 170 D5_Rolling_Counter "The current rolling counter value.";
CM_ SG_ 170 D1_PWM_Frequency "The inverter PWM frequency";
CM_ SG_ 170 D6_Start_Mode_Active "If in Key Switch Mode 1 then indicates status of Start input being applied.  0 = not active, 1 = active";
CM_ SG_ 169 D4_Reference_Voltage_12_0 "12V Input Voltage";
CM_ SG_ 169 D3_Reference_Voltage_5_0 "Transducer voltage";
CM_ SG_ 169 D2_Reference_Voltage_2_5 "Internal reference voltage";
CM_ SG_ 169 D1_Reference_Voltage_1_5 "Internal reference voltage";
CM_ SG_ 168 D4_Iq "The measured Iq current";
CM_ SG_ 168 D3_Id "The measured Id current";
CM_ SG_ 168 D2_Flux_Feedback "The estimated flux";
CM_ SG_ 168 D1_Flux_Command "The commanded flux";
CM_ SG_ 167 D4_VBC_Vq_Voltage "Measured value of the voltage between Phase B and Phase C";
CM_ SG_ 167 D3_VAB_Vd_Voltage "Measured value of the voltage betwen phase A and Phase B";
CM_ SG_ 167 D2_Output_Voltage "The calculated value of the output voltage, in peak line-neutral volts";
CM_ SG_ 167 D1_DC_Bus_Voltage "The actual measured value of the DC bus voltage";
CM_ SG_ 166 D4_DC_Bus_Current "The Calculated DC Bus Current";
CM_ SG_ 166 D3_Phase_C_Current "The measured value of Phase C current";
CM_ SG_ 166 D2_Phase_B_Current "The measured value of Phase B current";
CM_ SG_ 166 D1_Phase_A_Current "The measured value of Phase A current";
CM_ SG_ 165 D4_Delta_Resolver_Filtered "Used in calibration of resolver angle adjustment.";
CM_ SG_ 165 D3_Electrical_Output_Frequency "The actual electrical frequency of the inverter";
CM_ SG_ 165 D2_Motor_Speed "The measured speed of the motor";
CM_ SG_ 165 D1_Motor_Angle_Electrical "The Electrical Angle of the motor as read by the encoder or resolver";
CM_ SG_ 164 D5_Digital_Input_5 "Status of Digital Input #5";
CM_ SG_ 164 D4_Digital_Input_4 "Status of Digital Input #4";
CM_ SG_ 164 D3_Digital_Input_3 "Status of Digital Input #3";
CM_ SG_ 164 D2_Digital_Input_2 "Status of Digital Input #2";
CM_ SG_ 164 D1_Digital_Input_1 "Status of Digital Input #1";
CM_ SG_ 164 D6_Digital_Input_6 "Status of Digital Input #6";
CM_ SG_ 164 D7_Digital_Input_7 "Status of Digital Input #7";
CM_ SG_ 164 D8_Digital_Input_8 "Status of Digital Input #8";
CM_ SG_ 163 D4_Analog_Input_4 "Voltage on Analog Input #4";
CM_ SG_ 163 D3_Analog_Input_3 "Voltage on Analog Input #3";
CM_ SG_ 163 D2_Analog_Input_2 "Voltage on Analog Input #2";
CM_ SG_ 163 D1_Analog_Input_1 "Voltage on Analog Input #1";
CM_ SG_ 163 D5_Analog_Input_5 "Voltage on Analog Input #5";
CM_ SG_ 163 D6_Analog_Input_6 "Voltage on Analog Input #6";
CM_ SG_ 162 D4_Torque_Shudder "Shudder compensation value of torque";
CM_ SG_ 162 D3_Motor_Temperature "Motor Temperature Sensor";
CM_ SG_ 162 D2_RTD5_Temperature "RTD 5 (PT1000) Temperature (Gen 2 only)";
CM_ SG_ 162 D1_RTD4_Temperature "RTD 4 (PT1000) Temperature (Gen 2 only)";
CM_ SG_ 161 D4_RTD3_Temperature "RTD input 3 (PT1000) Temperature (Gen 2 only)";
CM_ SG_ 161 D3_RTD2_Temperature "RTD input 2 (PT1000) Temperature";
CM_ SG_ 161 D2_RTD1_Temperature "RTD input 1 (PT1000) Temperature";
CM_ SG_ 161 D1_Control_Board_Temperature "Control Board Temperature";
CM_ SG_ 160 D4_Gate_Driver_Board "Gate Driver Board Temperature";
CM_ SG_ 160 D3_Module_C "IGBT Module C Temperature";
CM_ SG_ 160 D2_Module_B "IGBT Module B Temperature";
CM_ SG_ 160 D1_Module_A "IGBT Module A Temperature";
CM_ BO_ 471 "Enable message sent to Delphi DC/DC converter.";
CM_ BO_ 469 "Response from Delphi DC/DC converter.";
CM_ BO_ 514 "Message sent by BMS for inverter DC current limiting.";
CM_ SG_ 514 D1_Max_Discharge_Current "Maximum discharge current from BMS";
CM_ SG_ 514 D2_Max_Charge_Current "Maximum charge current from BMS";
CM_ BO_ 176 "To enable fast message set CAN ACTIVE MSGS HI WORD to 0xFFFE.  Setting to default value of 0xFFFF will disable the fast message.";
CM_ SG_ 176 Fast_Torque_Command "The commanded torque";
CM_ SG_ 176 Fast_Torque_Feedback "The estimated torque";
CM_ SG_ 176 Fast_Motor_Speed "Motor speed";
CM_ SG_ 176 Fast_DC_Bus_Voltage "DC Bus Voltage";
BA_DEF_  "BusType" STRING ;
BA_DEF_ SG_  "SystemSignalLongSymbol" STRING ;
BA_DEF_DEF_  "BusType" "CAN";
BA_DEF_DEF_  "SystemSignalLongSymbol" "";
BA_ "SystemSignalLongSymbol" SG_ 469 D1_HV_Input_Current_Sensor_Valid "D1_HV_Input_Current_Sensor_Validity";
